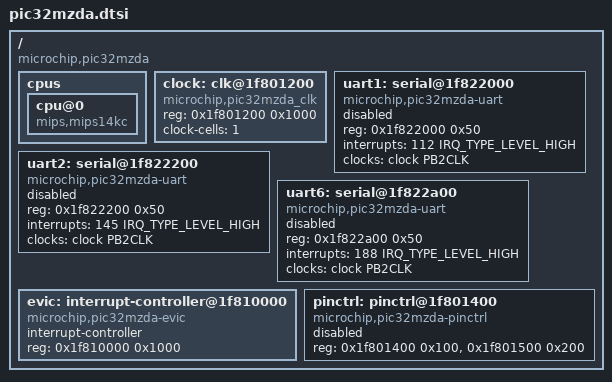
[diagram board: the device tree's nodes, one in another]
/*
 * Copyright 2015 Microchip Technology, Inc.
 * Purna Chandra Mandal, <purna.mandal@microchip.com>
 *
 * SPDX-License-Identifier:	GPL-2.0+
 */

#include <dt-bindings/interrupt-controller/irq.h>
#include <dt-bindings/clock/microchip,clock.h>
#include "skeleton.dtsi"

/ {
	compatible = "microchip,pic32mzda", "microchip,pic32mz";

	cpus {
		cpu@0 {
			compatible = "mips,mips14kc";
		};
	};

	clock: clk@1f801200 {
		compatible = "microchip,pic32mzda_clk";
		reg = <0x1f801200 0x1000>;
		clock-cells = <1>;
	};

	uart1: serial@1f822000 {
		compatible = "microchip,pic32mzda-uart";
		reg = <0x1f822000 0x50>;
		interrupts = <112 IRQ_TYPE_LEVEL_HIGH>;
		status = "disabled";
		clocks = <&clock PB2CLK>;
	};

	uart2: serial@1f822200 {
		compatible = "microchip,pic32mzda-uart";
		reg = <0x1f822200 0x50>;
		interrupts = <145 IRQ_TYPE_LEVEL_HIGH>;
		clocks = <&clock PB2CLK>;
		status = "disabled";
	};

	uart6: serial@1f822a00 {
		compatible = "microchip,pic32mzda-uart";
		reg = <0x1f822a00 0x50>;
		interrupts = <188 IRQ_TYPE_LEVEL_HIGH>;
		clocks = <&clock PB2CLK>;
		status = "disabled";
	};

	evic: interrupt-controller@1f810000 {
		compatible = "microchip,pic32mzda-evic";
		interrupt-controller;
		#interrupt-cells = <2>;
		reg = <0x1f810000 0x1000>;
	};

	pinctrl: pinctrl@1f801400 {
		compatible = "microchip,pic32mzda-pinctrl";
		reg = <0x1f801400 0x100>, /* in  */
		      <0x1f801500 0x200>; /* out */
		status = "disabled";
	};
};
